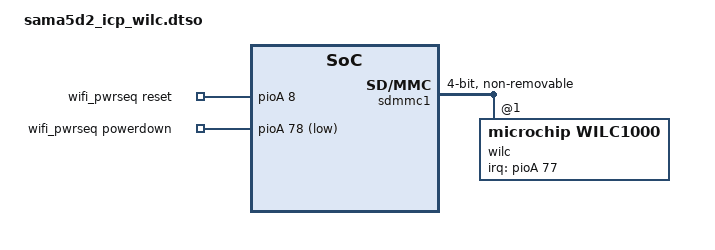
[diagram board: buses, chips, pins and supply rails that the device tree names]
// SPDX-License-Identifier: (GPL-2.0+ OR MIT)
/*
 * sama5d2_icp_wilc.dtso - Device Tree file for SAMA5D2-ICP board
 * overlay blob for ATWILC3000 - Wireless Modules.
 *
 * Copyright (C) 2019 Microchip Technology Inc. and its subsidiaries
 *
 * Author: Cristian Birsan <cristian.birsan@microchip.com>
 *
 */
/dts-v1/;
/plugin/;

#include <dt-bindings/gpio/gpio.h>
#include "sama5d2-pinfunc.h"

&{/ahb} {
	sdmmc1: sdio-host@b0000000 {
		pinctrl-names = "default";
		pinctrl-0 = <&pinctrl_sdmmc1_default>;
		bus-width = <4>;
		mmc-pwrseq = <&wifi_pwrseq>;
		#address-cells = <1>;
		#size-cells = <0>;
		no-1-8-v;
		non-removable;
		status = "okay";

		wilc: wilc@1 {
			compatible = "microchip,wilc1000", "microchip,wilc3000";
			reg = <1>;
			bus-width = <4>;
			irq-gpios = <&pioA 77 0>;
			status = "okay";
		};
	};
};

&{/} {
	wifi_pwrseq: wifi_pwrseq {
		compatible = "mmc-pwrseq-wilc";
		reset-gpios = <&pioA 8 GPIO_ACTIVE_HIGH>;
		powerdown-gpios = <&pioA 78 GPIO_ACTIVE_LOW>;
		pinctrl-0 = <&pinctrl_wilc_pwrseq_default>;
		pinctrl-names = "default";
		status = "okay"; /* Conflict with qspi1. */
	};
};

&pioA {
	pinctrl_sdmmc1_default: sdmmc1_default {
		cmd_data {
			pinmux = <PIN_PA18__SDMMC1_DAT0>,
					<PIN_PA19__SDMMC1_DAT1>,
					<PIN_PA20__SDMMC1_DAT2>,
					<PIN_PA21__SDMMC1_DAT3>;
			bias-disable;
		};

		ck_cd {
			pinmux = <PIN_PA22__SDMMC1_CK>,
					<PIN_PA28__SDMMC1_CMD>;
			bias-disable;
		};
	};

	pinctrl_wilc_pwrseq_default: wilc_pwrseq_default {
		pinmux = <PIN_PA8__GPIO>,
			 <PIN_PC15__GPIO>;
		bias-pull-up;
	};
};
